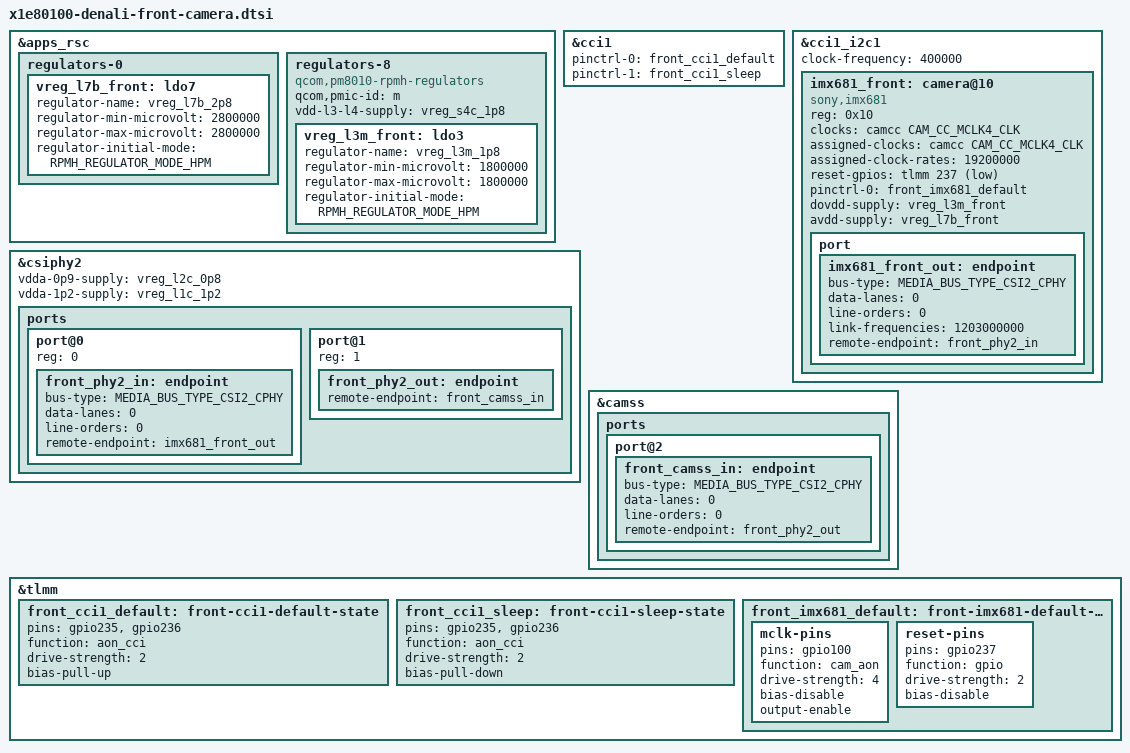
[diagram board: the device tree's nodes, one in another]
// SPDX-License-Identifier: GPL-2.0-only
/* Retained SP11 front wiring adapted to the standalone PHY API. */
#include <dt-bindings/media/video-interfaces.h>

&apps_rsc {
	regulators-0 {
		vreg_l7b_front: ldo7 {
			regulator-name = "vreg_l7b_2p8";
			regulator-min-microvolt = <2800000>;
			regulator-max-microvolt = <2800000>;
			regulator-initial-mode = <RPMH_REGULATOR_MODE_HPM>;
		};
	};

	regulators-8 {
		compatible = "qcom,pm8010-rpmh-regulators";
		qcom,pmic-id = "m";
		vdd-l3-l4-supply = <&vreg_s4c_1p8>;

		vreg_l3m_front: ldo3 {
			regulator-name = "vreg_l3m_1p8";
			regulator-min-microvolt = <1800000>;
			regulator-max-microvolt = <1800000>;
			regulator-initial-mode = <RPMH_REGULATOR_MODE_HPM>;
		};
	};
};

&cci1 {
	pinctrl-0 = <&front_cci1_default>;
	pinctrl-1 = <&front_cci1_sleep>;
	pinctrl-names = "default", "sleep";
	status = "okay";
};

&cci1_i2c1 {
	clock-frequency = <400000>;

	imx681_front: camera@10 {
		compatible = "sony,imx681";
		reg = <0x10>;
		clocks = <&camcc CAM_CC_MCLK4_CLK>;
		clock-names = "xclk";
		assigned-clocks = <&camcc CAM_CC_MCLK4_CLK>;
		assigned-clock-rates = <19200000>;
		reset-gpios = <&tlmm 237 GPIO_ACTIVE_LOW>;
		pinctrl-0 = <&front_imx681_default>;
		pinctrl-names = "default";
		dovdd-supply = <&vreg_l3m_front>;
		avdd-supply = <&vreg_l7b_front>;

		port {
			imx681_front_out: endpoint {
				bus-type = <MEDIA_BUS_TYPE_CSI2_CPHY>;
				data-lanes = <0>;
				line-orders = <0>;
				link-frequencies = /bits/ 64 <1203000000>;
				remote-endpoint = <&front_phy2_in>;
			};
		};
	};
};

&csiphy2 {
	/* Same shared supplies used by the retained native front graph. */
	vdda-0p9-supply = <&vreg_l2c_0p8>;
	vdda-1p2-supply = <&vreg_l1c_1p2>;
	status = "okay";

	ports {
		#address-cells = <1>;
		#size-cells = <0>;

		port@0 {
			reg = <0>;

			front_phy2_in: endpoint {
				bus-type = <MEDIA_BUS_TYPE_CSI2_CPHY>;
				data-lanes = <0>;
				line-orders = <0>;
				remote-endpoint = <&imx681_front_out>;
			};
		};

		port@1 {
			reg = <1>;

			front_phy2_out: endpoint {
				remote-endpoint = <&front_camss_in>;
			};
		};
	};
};

&camss {
	status = "okay";

	ports {
		port@2 {
			front_camss_in: endpoint {
				bus-type = <MEDIA_BUS_TYPE_CSI2_CPHY>;
				data-lanes = <0>;
				line-orders = <0>;
				remote-endpoint = <&front_phy2_out>;
			};
		};
	};
};

&tlmm {
	front_cci1_default: front-cci1-default-state {
		pins = "gpio235", "gpio236";
		function = "aon_cci";
		drive-strength = <2>;
		bias-pull-up;
	};

	front_cci1_sleep: front-cci1-sleep-state {
		pins = "gpio235", "gpio236";
		function = "aon_cci";
		drive-strength = <2>;
		bias-pull-down;
	};

	front_imx681_default: front-imx681-default-state {
		mclk-pins {
			pins = "gpio100";
			function = "cam_aon";
			drive-strength = <4>;
			bias-disable;
			output-enable;
		};

		reset-pins {
			pins = "gpio237";
			function = "gpio";
			drive-strength = <2>;
			bias-disable;
		};
	};
};
